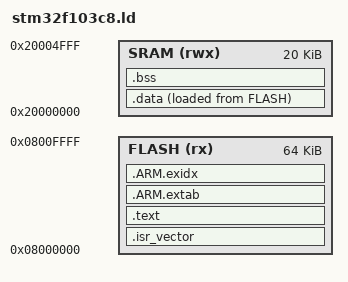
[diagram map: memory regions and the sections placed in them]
/* Linker script for STM32F103C8T6 — 64KB Flash, 20KB SRAM */

MEMORY
{
    FLASH (rx)  : ORIGIN = 0x08000000, LENGTH = 64K
    SRAM  (rwx) : ORIGIN = 0x20000000, LENGTH = 20K
}

_estack = ORIGIN(SRAM) + LENGTH(SRAM);

SECTIONS
{
    .isr_vector :
    {
        KEEP(*(.isr_vector))
        . = ALIGN(4);
    } > FLASH

    .text :
    {
        . = ALIGN(4);
        *(.text)
        *(.text*)
        *(.rodata)
        *(.rodata*)
        *(.glue_7)
        *(.glue_7t)
        KEEP(*(.init))
        KEEP(*(.fini))
        . = ALIGN(4);
        _etext = .;
    } > FLASH

    .ARM.extab :
    {
        *(.ARM.extab* .gnu.linkonce.armextab.*)
    } > FLASH

    .ARM.exidx :
    {
        __exidx_start = .;
        *(.ARM.exidx* .gnu.linkonce.armexidx.*)
        __exidx_end = .;
    } > FLASH

    _sidata = LOADADDR(.data);

    .data :
    {
        . = ALIGN(4);
        _sdata = .;
        *(.data)
        *(.data*)
        . = ALIGN(4);
        _edata = .;
    } > SRAM AT> FLASH

    .bss (NOLOAD) :
    {
        . = ALIGN(4);
        _sbss = .;
        *(.bss)
        *(.bss*)
        *(COMMON)
        . = ALIGN(4);
        _ebss = .;
    } > SRAM
}
